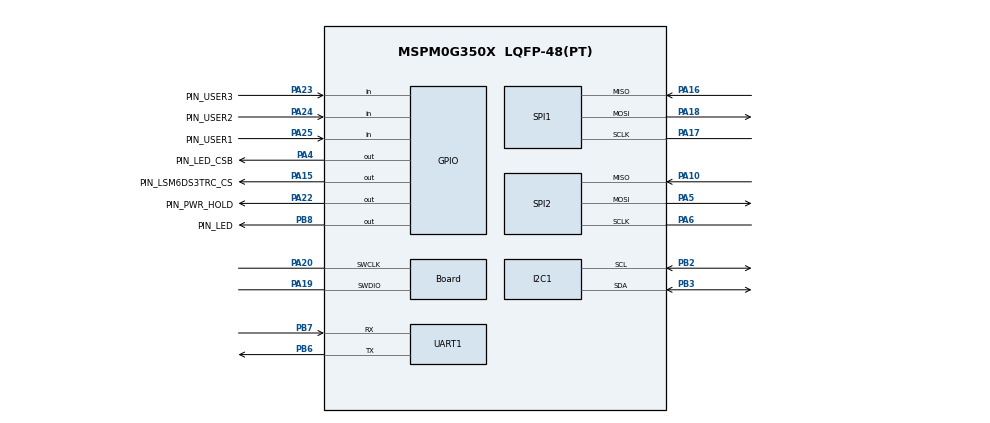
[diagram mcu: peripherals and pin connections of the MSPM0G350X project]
/**
 * @cliArgs --device "MSPM0G350X" --part "Default" --package "LQFP-48(PT)" --product "mspm0_sdk@2.10.00.04"
 * @versions {"tool":"1.27.0+4565"}
 */

/**
 * Import the modules used in this configuration.
 */
const ADC12   = scripting.addModule("/ti/driverlib/ADC12", {}, false);
const ADC121  = ADC12.addInstance();
const GPIO    = scripting.addModule("/ti/driverlib/GPIO", {}, false);
const GPIO1   = GPIO.addInstance();
const GPIO2   = GPIO.addInstance();
const GPIO3   = GPIO.addInstance();
const GPIO4   = GPIO.addInstance();
const GPIO5   = GPIO.addInstance();
const I2C     = scripting.addModule("/ti/driverlib/I2C", {}, false);
const I2C1    = I2C.addInstance();
const MATHACL = scripting.addModule("/ti/driverlib/MATHACL");
const SPI     = scripting.addModule("/ti/driverlib/SPI", {}, false);
const SPI1    = SPI.addInstance();
const SPI2    = SPI.addInstance();
const SYSCTL  = scripting.addModule("/ti/driverlib/SYSCTL");
const TIMER   = scripting.addModule("/ti/driverlib/TIMER", {}, false);
const TIMER1  = TIMER.addInstance();
const UART    = scripting.addModule("/ti/driverlib/UART", {}, false);
const UART1   = UART.addInstance();

/**
 * Write custom configuration values to the imported modules.
 */
ADC121.$name                             = "BAT_ADC";
ADC121.sampClkSrc                        = "DL_ADC12_CLOCK_ULPCLK";
ADC121.sampClkDiv                        = "DL_ADC12_CLOCK_DIVIDE_8";
ADC121.sampleTime0                       = "125 us";
ADC121.enabledInterrupts                 = ["DL_ADC12_INTERRUPT_MEM0_RESULT_LOADED"];
ADC121.powerDownMode                     = "DL_ADC12_POWER_DOWN_MODE_MANUAL";
ADC121.peripheral.$assign                = "ADC0";
ADC121.peripheral.adcPin0.$assign        = "PA27";
ADC121.adcPin0Config.$name               = "ti_driverlib_gpio_GPIOPinGeneric0";
ADC121.adcPin0Config.hideOutputInversion = scripting.forceWrite(false);

const Board                       = scripting.addModule("/ti/driverlib/Board", {}, false);
Board.peripheral.$assign          = "DEBUGSS";
Board.peripheral.swclkPin.$assign = "PA20";
Board.peripheral.swdioPin.$assign = "PA19";

GPIO1.$name                         = "GPIO_LSM6DS3TRC";
GPIO1.associatedPins[0].$name       = "PIN_LSM6DS3TRC_CS";
GPIO1.associatedPins[0].pin.$assign = "PA15";

GPIO2.$name                         = "LED";
GPIO2.associatedPins[0].$name       = "PIN_LED";
GPIO2.associatedPins[0].pin.$assign = "PB8";

GPIO3.$name                          = "GPIO_LED_DRV";
GPIO3.associatedPins[0].$name        = "PIN_LED_CSB";
GPIO3.associatedPins[0].initialValue = "SET";
GPIO3.associatedPins[0].pin.$assign  = "PA4";

GPIO4.$name                          = "GPIO_PWR";
GPIO4.associatedPins[0].$name        = "PIN_PWR_HOLD";
GPIO4.associatedPins[0].initialValue = "SET";
GPIO4.associatedPins[0].pin.$assign  = "PA22";

GPIO5.$name                              = "GPIO_USERKEY";
GPIO5.associatedPins.create(3);
GPIO5.associatedPins[0].$name            = "PIN_USER3";
GPIO5.associatedPins[0].direction        = "INPUT";
GPIO5.associatedPins[0].internalResistor = "NONE";
GPIO5.associatedPins[0].pin.$assign      = "PA23";
GPIO5.associatedPins[1].$name            = "PIN_USER2";
GPIO5.associatedPins[1].direction        = "INPUT";
GPIO5.associatedPins[1].internalResistor = "NONE";
GPIO5.associatedPins[1].pin.$assign      = "PA24";
GPIO5.associatedPins[2].$name            = "PIN_USER1";
GPIO5.associatedPins[2].direction        = "INPUT";
GPIO5.associatedPins[2].internalResistor = "PULL_UP";
GPIO5.associatedPins[2].pin.$assign      = "PA25";

I2C1.basicEnableController             = true;
I2C1.$name                             = "I2C_OLED";
I2C1.basicControllerStandardBusSpeed   = "FastPlus";
I2C1.peripheral.$assign                = "I2C1";
I2C1.peripheral.sdaPin.$assign         = "PB3";
I2C1.peripheral.sclPin.$assign         = "PB2";
I2C1.sdaPinConfig.hideOutputInversion  = scripting.forceWrite(false);
I2C1.sdaPinConfig.onlyInternalResistor = scripting.forceWrite(false);
I2C1.sdaPinConfig.passedPeripheralType = scripting.forceWrite("Digital");
I2C1.sdaPinConfig.$name                = "ti_driverlib_gpio_GPIOPinGeneric4";
I2C1.sclPinConfig.hideOutputInversion  = scripting.forceWrite(false);
I2C1.sclPinConfig.onlyInternalResistor = scripting.forceWrite(false);
I2C1.sclPinConfig.passedPeripheralType = scripting.forceWrite("Digital");
I2C1.sclPinConfig.$name                = "ti_driverlib_gpio_GPIOPinGeneric5";

SPI1.$name                              = "SPI_LSM6DS3TRC";
SPI1.frameFormat                        = "MOTO3";
SPI1.sclkPinConfig.direction            = scripting.forceWrite("OUTPUT");
SPI1.sclkPinConfig.onlyInternalResistor = scripting.forceWrite(false);
SPI1.sclkPinConfig.passedPeripheralType = scripting.forceWrite("Digital");
SPI1.sclkPinConfig.$name                = "ti_driverlib_gpio_GPIOPinGeneric9";
SPI1.mosiPinConfig.direction            = scripting.forceWrite("OUTPUT");
SPI1.mosiPinConfig.hideOutputInversion  = scripting.forceWrite(false);
SPI1.mosiPinConfig.onlyInternalResistor = scripting.forceWrite(false);
SPI1.mosiPinConfig.passedPeripheralType = scripting.forceWrite("Digital");
SPI1.mosiPinConfig.$name                = "ti_driverlib_gpio_GPIOPinGeneric11";
SPI1.misoPinConfig.onlyInternalResistor = scripting.forceWrite(false);
SPI1.misoPinConfig.passedPeripheralType = scripting.forceWrite("Digital");
SPI1.misoPinConfig.$name                = "ti_driverlib_gpio_GPIOPinGeneric12";
SPI1.peripheral.$assign                 = "SPI1";
SPI1.peripheral.sclkPin.$assign         = "PA17";
SPI1.peripheral.mosiPin.$assign         = "PA18";
SPI1.peripheral.misoPin.$assign         = "PA16";

SPI2.$name                              = "SPI_LED_DRV";
SPI2.frameFormat                        = "MOTO3";
SPI2.targetBitRate                      = 2000000;
SPI2.sclkPinConfig.direction            = scripting.forceWrite("OUTPUT");
SPI2.sclkPinConfig.onlyInternalResistor = scripting.forceWrite(false);
SPI2.sclkPinConfig.passedPeripheralType = scripting.forceWrite("Digital");
SPI2.sclkPinConfig.$name                = "ti_driverlib_gpio_GPIOPinGeneric15";
SPI2.mosiPinConfig.direction            = scripting.forceWrite("OUTPUT");
SPI2.mosiPinConfig.hideOutputInversion  = scripting.forceWrite(false);
SPI2.mosiPinConfig.onlyInternalResistor = scripting.forceWrite(false);
SPI2.mosiPinConfig.passedPeripheralType = scripting.forceWrite("Digital");
SPI2.mosiPinConfig.$name                = "ti_driverlib_gpio_GPIOPinGeneric16";
SPI2.misoPinConfig.onlyInternalResistor = scripting.forceWrite(false);
SPI2.misoPinConfig.passedPeripheralType = scripting.forceWrite("Digital");
SPI2.misoPinConfig.$name                = "ti_driverlib_gpio_GPIOPinGeneric17";
SPI2.peripheral.$assign                 = "SPI0";
SPI2.peripheral.sclkPin.$assign         = "PA6";
SPI2.peripheral.mosiPin.$assign         = "PA5";
SPI2.peripheral.misoPin.$assign         = "PA10";

SYSCTL.SYSPLL_CLK2XEn     = true;
SYSCTL.SYSPLL_Pdiv        = 1;
SYSCTL.SYSPLL_Qdiv        = 5;
SYSCTL.SYSPLL_CLK2XDiv    = 3;
SYSCTL.MCLKSource         = "HSCLK";
SYSCTL.HSCLKSource        = "SYSPLLCLK2X";
SYSCTL.validateClkStatus  = true;
SYSCTL.MFPCLKEn           = true;
SYSCTL.UDIV               = "2";
SYSCTL.peripheral.$assign = "SYSCTL";

TIMER1.$name              = "TIMER_0";
TIMER1.timerMode          = "PERIODIC";
TIMER1.timerPeriod        = "5 ms";
TIMER1.timerStartTimer    = true;
TIMER1.interrupts         = ["ZERO"];
TIMER1.timerClkDiv        = 8;
TIMER1.peripheral.$assign = "TIMA0";

UART1.$name                    = "UART_0";
UART1.targetBaudRate           = 115200;
UART1.enabledInterrupts        = ["RX"];
UART1.peripheral.$assign       = "UART1";
UART1.peripheral.rxPin.$assign = "PB7";
UART1.peripheral.txPin.$assign = "PB6";
UART1.txPinConfig.$name        = "ti_driverlib_gpio_GPIOPinGeneric2";
UART1.rxPinConfig.$name        = "ti_driverlib_gpio_GPIOPinGeneric3";

const ProjectConfig              = scripting.addModule("/ti/project_config/ProjectConfig", {}, false);
ProjectConfig.migrationCondition = true;
